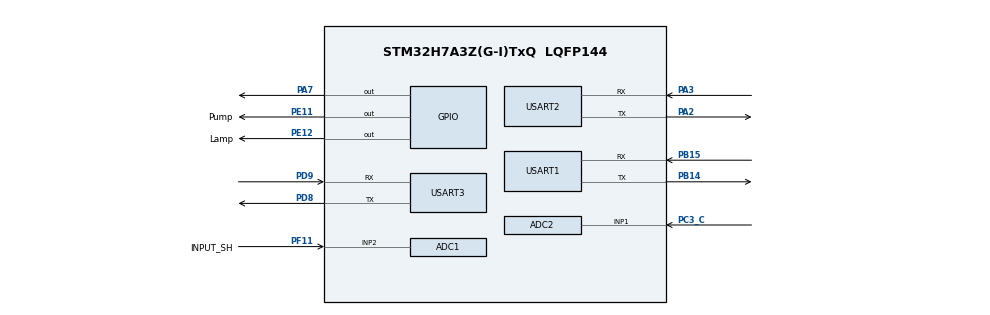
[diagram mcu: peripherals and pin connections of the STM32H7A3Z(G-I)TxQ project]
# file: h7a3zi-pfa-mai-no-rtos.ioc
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ADC1.Channel-0\#ChannelRegularConversion=ADC_CHANNEL_2
ADC1.NbrOfConversionFlag=1
ADC1.OffsetNumber-0\#ChannelRegularConversion=ADC_OFFSET_NONE
ADC1.OffsetSignedSaturation-0\#ChannelRegularConversion=DISABLE
ADC1.Rank-0\#ChannelRegularConversion=1
ADC1.SamplingTime-0\#ChannelRegularConversion=ADC_SAMPLETIME_1CYCLE_5
ADC1.master=1
ADC2.Channel-0\#ChannelRegularConversion=ADC_CHANNEL_1
ADC2.NbrOfConversionFlag=1
ADC2.OffsetNumber-0\#ChannelRegularConversion=ADC_OFFSET_NONE
ADC2.OffsetSignedSaturation-0\#ChannelRegularConversion=DISABLE
ADC2.Rank-0\#ChannelRegularConversion=1
ADC2.SamplingTime-0\#ChannelRegularConversion=ADC_SAMPLETIME_1CYCLE_5
Mcu.Family=STM32H7
Mcu.Name=STM32H7A3Z(G-I)TxQ
Mcu.Package=LQFP144
NVIC.PriorityGroup=NVIC_PRIORITYGROUP_4
PA2.Mode=Asynchronous
PA2.Signal=USART2_TX
PA3.Mode=Asynchronous
PA3.Signal=USART2_RX
PA7.Signal=GPIO_Output
PB14.Mode=Asynchronous
PB14.Signal=USART1_TX
PB15.Mode=Asynchronous
PB15.Signal=USART1_RX
PC3_C.Mode=IN1-Single-Ended
PC3_C.Signal=ADC2_INP1
PD8.Mode=Asynchronous
PD8.Signal=USART3_TX
PD9.Mode=Asynchronous
PD9.Signal=USART3_RX
PE11.GPIO_Label=Pump
PE11.Signal=GPIO_Output
PE12.GPIO_Label=Lamp
PE12.Signal=GPIO_Output
PF11.GPIO_Label=INPUT_SH
PF11.Mode=IN2-Single-Ended
PF11.Signal=ADC1_INP2
PH0-OSC_IN.Mode=HSE-External-Oscillator
PH0-OSC_IN.Signal=RCC_OSC_IN
PH1-OSC_OUT.Mode=HSE-External-Oscillator
PH1-OSC_OUT.Signal=RCC_OSC_OUT
ProjectManager.HeapSize=0x200
ProjectManager.StackSize=0x400
ProjectManager.TargetToolchain=STM32CubeIDE
RCC.ADCFreq_Value=42666666.666666664
RCC.APB1Freq_Value=64000000
RCC.APB2Freq_Value=64000000
RCC.APB3Freq_Value=64000000
RCC.APB4Freq_Value=64000000
RCC.CortexFreq_Value=64000000
RCC.DIVM1=4
RCC.DIVM2=4
RCC.DIVM3=1
RCC.DIVN1=8
RCC.DIVN2=8
RCC.DIVN3=24
RCC.DIVP2=3
RCC.DIVQ1=4
RCC.HCLKFreq_Value=64000000
RCC.HSE_VALUE=8000000
RCC.PLL2FRACN=0
RCC.PLLFRACN=0
RCC.PWR_Regulator_Voltage_Scale=PWR_REGULATOR_VOLTAGE_SCALE0
RCC.SYSCLKFreq_VALUE=64000000
RCC.SYSCLKSource=RCC_SYSCLKSOURCE_PLLCLK
RCC.SupplySource=PWR_DIRECT_SMPS_SUPPLY
RCC.USBCLockSelection=RCC_USBCLKSOURCE_HSI48
RCC.USBFreq_Value=48000000
USART1.VirtualMode-Asynchronous=VM_ASYNC
USART2.VirtualMode-Asynchronous=VM_ASYNC
USART3.VirtualMode-Asynchronous=VM_ASYNC
VP_TIM6_VS_ClockSourceINT.Mode=Enable_Timer
board=NUCLEO-H7A3ZI-Q

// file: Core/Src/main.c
/* USER CODE BEGIN Header */
/**
  ******************************************************************************
  * @file           : main.c
  * @brief          : Main program body
  ******************************************************************************
  * @attention
  *
  * Copyright (c) 2024 STMicroelectronics.
  * All rights reserved.
  *
  * This software is licensed under terms that can be found in the LICENSE file
  * in the root directory of this software component.
  * If no LICENSE file comes with this software, it is provided AS-IS.
  *
  ******************************************************************************
  */
/* USER CODE END Header */
#include "main.h"

/* USER CODE BEGIN Includes */
#include <string.h>
#include <stdio.h>
#include "DHT.h"
#include "stdint.h"
/* USER CODE END Includes */

ADC_HandleTypeDef hadc1;
ADC_HandleTypeDef hadc2;

TIM_HandleTypeDef htim6;

UART_HandleTypeDef huart1;
UART_HandleTypeDef huart2;
UART_HandleTypeDef huart3;

/* USER CODE BEGIN PV */
DHT_DataTypedef DHT11_Data;
/* USER CODE END PV */

void SystemClock_Config(void);
void PeriphCommonClock_Config(void);
static void MX_GPIO_Init(void);
static void MX_ADC1_Init(void);
static void MX_USART1_UART_Init(void);
static void MX_USART2_UART_Init(void);
static void MX_TIM6_Init(void);
static void MX_USART3_UART_Init(void);
static void MX_ADC2_Init(void);

/* USER CODE BEGIN 0 */
// Function to send a string via UART

void UART_SendString(UART_HandleTypeDef *huart, const char *str);
void UART_GetString(UART_HandleTypeDef *huart, char *str, int size);
void DHT_Init(void);
void Read_DataDHT(float *temperature, float *humidity);
float Read_Soil_Humidity(void);
float Read_Soil_Luminosity(void);
void ESP01_Init(void);
void ESP01_SendATCommands(float temperature, float humidity, float soilHumidity, float luminosity, int lamp_stat, int pump_stat);

int main(void) {
    float temperature, humidity, soilHumidity, luminosity;
    int lamp_stat = 0;
    int pump_stat = 0;
    HAL_Init();
    SystemClock_Config();
    PeriphCommonClock_Config();
    MX_GPIO_Init();
    MX_ADC1_Init();
    MX_USART1_UART_Init();
    MX_USART2_UART_Init();
    MX_TIM6_Init();
    MX_USART3_UART_Init();
    MX_ADC2_Init();

    DHT_Init();
    ESP01_Init();

    while (1) {
        Read_DataDHT(&temperature, &humidity);
        soilHumidity = Read_Soil_Humidity();
        luminosity = Read_Soil_Luminosity();

        lamp_stat = (luminosity < 100) ? 1 : 0;
        pump_stat = (soilHumidity < 30) ? 1 : 0;
        HAL_GPIO_WritePin(GPIOE, Pump_Pin, !pump_stat);
        HAL_GPIO_WritePin(GPIOE, Lamp_Pin, !lamp_stat);
        ESP01_SendATCommands(temperature, humidity, soilHumidity, luminosity, lamp_stat, pump_stat);
    }
}

void UART_SendString(UART_HandleTypeDef *huart, const char *str) {
    HAL_UART_Transmit(huart, (uint8_t*)str, strlen(str), HAL_MAX_DELAY);
}

void DHT_Init(void) {
    // Add initialization code for DHT sensor if needed
}

void Read_DataDHT(float *temperature, float *humidity) {
    DHT_GetData(&DHT11_Data);
    *temperature = DHT11_Data.Temperature;
    *humidity = DHT11_Data.Humidity;
}

float Read_Soil_Humidity(void) {
    HAL_ADC_Start(&hadc1);
    HAL_ADC_PollForConversion(&hadc1, 20);
    uint32_t adcValue = HAL_ADC_GetValue(&hadc1);
    HAL_ADC_Stop(&hadc1);
    return ((float)(65535 - adcValue) / 43535) * 100.0;
}

float Read_Soil_Luminosity(void) {
    HAL_ADC_Start(&hadc2);
    HAL_ADC_PollForConversion(&hadc2, 20);
    uint32_t adcValue = HAL_ADC_GetValue(&hadc2);
    HAL_ADC_Stop(&hadc2);
    return ((float)(65535 - adcValue) / 43535) * 100.0;
}

void ESP01_Init(void) {
    const char* commands[] = {
        "AT+CWMODE=1\r\n",
        "AT+CWJAP=\"D2F3794\",\"malek123\"\r\n",
        "AT+CIPMUX=0\r\n"
    };
    for (int i = 0; i < sizeof(commands) / sizeof(commands[0]); ++i) {
        UART_SendString(&huart2, commands[i]);
        UART_SendString(&huart3, commands[i]);
        HAL_Delay((i == 1) ? 5000 : 1000);
    }
}

void ESP01_SendATCommands(float temperature, float humidity, float soilHumidity, float luminosity, int lamp_stat, int pump_stat) {
    char cmd[256];

    // Start TCP connection
    UART_SendString(&huart2, "AT+CIPSTART=\"TCP\",\"api.thingspeak.com\",80\r\n");
    UART_SendString(&huart3, "AT+CIPSTART=\"TCP\",\"api.thingspeak.com\",80\r\n");
    HAL_Delay(250);

    // Prepare to send the sensor data
    UART_SendString(&huart2, "AT+CIPSEND=150\r\n");
    UART_SendString(&huart3, "AT+CIPSEND=150\r\n");
    HAL_Delay(250);

    snprintf(cmd, sizeof(cmd),
        "GET https://api.thingspeak.com/update?api_key=5QWLEBMD4I1BHKEA&field1=%.2f&field2=%.2f&field3=%.2f&field4=%.2f&field5=%d&field6=%d\r\n",
        temperature, humidity, soilHumidity, luminosity, lamp_stat, pump_stat);

    // Send the data
    UART_SendString(&huart2, cmd);
    UART_SendString(&huart3, cmd);
    HAL_Delay(250);
}

void SystemClock_Config(void)
{
  RCC_OscInitTypeDef RCC_OscInitStruct = {0};
  RCC_ClkInitTypeDef RCC_ClkInitStruct = {0};

  /*AXI clock gating */
  RCC->CKGAENR = 0xFFFFFFFF;

  /** Supply configuration update enable
  */
  HAL_PWREx_ConfigSupply(PWR_DIRECT_SMPS_SUPPLY);

  /** Configure the main internal regulator output voltage
  */
  __HAL_PWR_VOLTAGESCALING_CONFIG(PWR_REGULATOR_VOLTAGE_SCALE0);

  while(!__HAL_PWR_GET_FLAG(PWR_FLAG_VOSRDY)) {}

  /** Initializes the RCC Oscillators according to the specified parameters
  * in the RCC_OscInitTypeDef structure.
  */
  RCC_OscInitStruct.OscillatorType = RCC_OSCILLATORTYPE_HSI;
  RCC_OscInitStruct.HSIState = RCC_HSI_DIV1;
  RCC_OscInitStruct.HSICalibrationValue = 64;
  RCC_OscInitStruct.PLL.PLLState = RCC_PLL_ON;
  RCC_OscInitStruct.PLL.PLLSource = RCC_PLLSOURCE_HSI;
  RCC_OscInitStruct.PLL.PLLM = 4;
  RCC_OscInitStruct.PLL.PLLN = 8;
  RCC_OscInitStruct.PLL.PLLP = 2;
  RCC_OscInitStruct.PLL.PLLQ = 4;
  RCC_OscInitStruct.PLL.PLLR = 2;
  RCC_OscInitStruct.PLL.PLLRGE = RCC_PLL1VCIRANGE_3;
  RCC_OscInitStruct.PLL.PLLVCOSEL = RCC_PLL1VCOWIDE;
  RCC_OscInitStruct.PLL.PLLFRACN = 0;
  if (HAL_RCC_OscConfig(&RCC_OscInitStruct) != HAL_OK)
  {
    Error_Handler();
  }

  /** Initializes the CPU, AHB and APB buses clocks
  */
  RCC_ClkInitStruct.ClockType = RCC_CLOCKTYPE_HCLK|RCC_CLOCKTYPE_SYSCLK
                              |RCC_CLOCKTYPE_PCLK1|RCC_CLOCKTYPE_PCLK2
                              |RCC_CLOCKTYPE_D3PCLK1|RCC_CLOCKTYPE_D1PCLK1;
  RCC_ClkInitStruct.SYSCLKSource = RCC_SYSCLKSOURCE_PLLCLK;
  RCC_ClkInitStruct.SYSCLKDivider = RCC_SYSCLK_DIV1;
  RCC_ClkInitStruct.AHBCLKDivider = RCC_HCLK_DIV1;
  RCC_ClkInitStruct.APB3CLKDivider = RCC_APB3_DIV1;
  RCC_ClkInitStruct.APB1CLKDivider = RCC_APB1_DIV1;
  RCC_ClkInitStruct.APB2CLKDivider = RCC_APB2_DIV1;
  RCC_ClkInitStruct.APB4CLKDivider = RCC_APB4_DIV1;

  if (HAL_RCC_ClockConfig(&RCC_ClkInitStruct, FLASH_LATENCY_1) != HAL_OK)
  {
    Error_Handler();
  }
}

void PeriphCommonClock_Config(void)
{
  RCC_PeriphCLKInitTypeDef PeriphClkInitStruct = {0};

  /** Initializes the peripherals clock
  */
  PeriphClkInitStruct.PeriphClockSelection = RCC_PERIPHCLK_ADC;
  PeriphClkInitStruct.PLL2.PLL2M = 4;
  PeriphClkInitStruct.PLL2.PLL2N = 8;
  PeriphClkInitStruct.PLL2.PLL2P = 3;
  PeriphClkInitStruct.PLL2.PLL2Q = 2;
  PeriphClkInitStruct.PLL2.PLL2R = 2;
  PeriphClkInitStruct.PLL2.PLL2RGE = RCC_PLL2VCIRANGE_3;
  PeriphClkInitStruct.PLL2.PLL2VCOSEL = RCC_PLL2VCOWIDE;
  PeriphClkInitStruct.PLL2.PLL2FRACN = 0;
  PeriphClkInitStruct.AdcClockSelection = RCC_ADCCLKSOURCE_PLL2;
  if (HAL_RCCEx_PeriphCLKConfig(&PeriphClkInitStruct) != HAL_OK)
  {
    Error_Handler();
  }
}

static void MX_ADC1_Init(void)
{

  ADC_MultiModeTypeDef multimode = {0};
  ADC_ChannelConfTypeDef sConfig = {0};

  /** Common config
  */
  hadc1.Instance = ADC1;
  hadc1.Init.ClockPrescaler = ADC_CLOCK_ASYNC_DIV1;
  hadc1.Init.Resolution = ADC_RESOLUTION_16B;
  hadc1.Init.ScanConvMode = ADC_SCAN_DISABLE;
  hadc1.Init.EOCSelection = ADC_EOC_SINGLE_CONV;
  hadc1.Init.LowPowerAutoWait = DISABLE;
  hadc1.Init.ContinuousConvMode = DISABLE;
  hadc1.Init.NbrOfConversion = 1;
  hadc1.Init.DiscontinuousConvMode = DISABLE;
  hadc1.Init.ExternalTrigConv = ADC_SOFTWARE_START;
  hadc1.Init.ExternalTrigConvEdge = ADC_EXTERNALTRIGCONVEDGE_NONE;
  hadc1.Init.ConversionDataManagement = ADC_CONVERSIONDATA_DR;
  hadc1.Init.Overrun = ADC_OVR_DATA_PRESERVED;
  hadc1.Init.LeftBitShift = ADC_LEFTBITSHIFT_NONE;
  hadc1.Init.OversamplingMode = DISABLE;
  if (HAL_ADC_Init(&hadc1) != HAL_OK)
  {
    Error_Handler();
  }

  /** Configure the ADC multi-mode
  */
  multimode.Mode = ADC_MODE_INDEPENDENT;
  if (HAL_ADCEx_MultiModeConfigChannel(&hadc1, &multimode) != HAL_OK)
  {
    Error_Handler();
  }

  /** Configure Regular Channel
  */
  sConfig.Channel = ADC_CHANNEL_2;
  sConfig.Rank = ADC_REGULAR_RANK_1;
  sConfig.SamplingTime = ADC_SAMPLETIME_1CYCLE_5;
  sConfig.SingleDiff = ADC_SINGLE_ENDED;
  sConfig.OffsetNumber = ADC_OFFSET_NONE;
  sConfig.Offset = 0;
  sConfig.OffsetSignedSaturation = DISABLE;
  if (HAL_ADC_ConfigChannel(&hadc1, &sConfig) != HAL_OK)
  {
    Error_Handler();
  }

}

static void MX_ADC2_Init(void)
{

  ADC_ChannelConfTypeDef sConfig = {0};

  /** Common config
  */
  hadc2.Instance = ADC2;
  hadc2.Init.ClockPrescaler = ADC_CLOCK_ASYNC_DIV1;
  hadc2.Init.Resolution = ADC_RESOLUTION_16B;
  hadc2.Init.ScanConvMode = ADC_SCAN_DISABLE;
  hadc2.Init.EOCSelection = ADC_EOC_SINGLE_CONV;
  hadc2.Init.LowPowerAutoWait = DISABLE;
  hadc2.Init.ContinuousConvMode = DISABLE;
  hadc2.Init.NbrOfConversion = 1;
  hadc2.Init.DiscontinuousConvMode = DISABLE;
  hadc2.Init.ExternalTrigConv = ADC_SOFTWARE_START;
  hadc2.Init.ExternalTrigConvEdge = ADC_EXTERNALTRIGCONVEDGE_NONE;
  hadc2.Init.ConversionDataManagement = ADC_CONVERSIONDATA_DR;
  hadc2.Init.Overrun = ADC_OVR_DATA_PRESERVED;
  hadc2.Init.LeftBitShift = ADC_LEFTBITSHIFT_NONE;
  hadc2.Init.OversamplingMode = DISABLE;
  if (HAL_ADC_Init(&hadc2) != HAL_OK)
  {
    Error_Handler();
  }

  /** Configure Regular Channel
  */
  sConfig.Channel = ADC_CHANNEL_1;
  sConfig.Rank = ADC_REGULAR_RANK_1;
  sConfig.SamplingTime = ADC_SAMPLETIME_1CYCLE_5;
  sConfig.SingleDiff = ADC_SINGLE_ENDED;
  sConfig.OffsetNumber = ADC_OFFSET_NONE;
  sConfig.Offset = 0;
  sConfig.OffsetSignedSaturation = DISABLE;
  if (HAL_ADC_ConfigChannel(&hadc2, &sConfig) != HAL_OK)
  {
    Error_Handler();
  }

}

static void MX_TIM6_Init(void)
{

  TIM_MasterConfigTypeDef sMasterConfig = {0};

  htim6.Instance = TIM6;
  htim6.Init.Prescaler = 0;
  htim6.Init.CounterMode = TIM_COUNTERMODE_UP;
  htim6.Init.Period = 65535;
  htim6.Init.AutoReloadPreload = TIM_AUTORELOAD_PRELOAD_DISABLE;
  if (HAL_TIM_Base_Init(&htim6) != HAL_OK)
  {
    Error_Handler();
  }
  sMasterConfig.MasterOutputTrigger = TIM_TRGO_RESET;
  sMasterConfig.MasterSlaveMode = TIM_MASTERSLAVEMODE_DISABLE;
  if (HAL_TIMEx_MasterConfigSynchronization(&htim6, &sMasterConfig) != HAL_OK)
  {
    Error_Handler();
  }

}

static void MX_USART1_UART_Init(void)
{

  huart1.Instance = USART1;
  huart1.Init.BaudRate = 115200;
  huart1.Init.WordLength = UART_WORDLENGTH_8B;
  huart1.Init.StopBits = UART_STOPBITS_1;
  huart1.Init.Parity = UART_PARITY_NONE;
  huart1.Init.Mode = UART_MODE_TX_RX;
  huart1.Init.HwFlowCtl = UART_HWCONTROL_NONE;
  huart1.Init.OverSampling = UART_OVERSAMPLING_16;
  huart1.Init.OneBitSampling = UART_ONE_BIT_SAMPLE_DISABLE;
  huart1.Init.ClockPrescaler = UART_PRESCALER_DIV1;
  huart1.AdvancedInit.AdvFeatureInit = UART_ADVFEATURE_NO_INIT;
  if (HAL_UART_Init(&huart1) != HAL_OK)
  {
    Error_Handler();
  }
  if (HAL_UARTEx_SetTxFifoThreshold(&huart1, UART_TXFIFO_THRESHOLD_1_8) != HAL_OK)
  {
    Error_Handler();
  }
  if (HAL_UARTEx_SetRxFifoThreshold(&huart1, UART_RXFIFO_THRESHOLD_1_8) != HAL_OK)
  {
    Error_Handler();
  }
  if (HAL_UARTEx_DisableFifoMode(&huart1) != HAL_OK)
  {
    Error_Handler();
  }

}

static void MX_USART2_UART_Init(void)
{

  huart2.Instance = USART2;
  huart2.Init.BaudRate = 115200;
  huart2.Init.WordLength = UART_WORDLENGTH_8B;
  huart2.Init.StopBits = UART_STOPBITS_1;
  huart2.Init.Parity = UART_PARITY_NONE;
  huart2.Init.Mode = UART_MODE_TX_RX;
  huart2.Init.HwFlowCtl = UART_HWCONTROL_NONE;
  huart2.Init.OverSampling = UART_OVERSAMPLING_16;
  huart2.Init.OneBitSampling = UART_ONE_BIT_SAMPLE_DISABLE;
  huart2.Init.ClockPrescaler = UART_PRESCALER_DIV1;
  huart2.AdvancedInit.AdvFeatureInit = UART_ADVFEATURE_NO_INIT;
  if (HAL_UART_Init(&huart2) != HAL_OK)
  {
    Error_Handler();
  }
  if (HAL_UARTEx_SetTxFifoThreshold(&huart2, UART_TXFIFO_THRESHOLD_1_8) != HAL_OK)
  {
    Error_Handler();
  }
  if (HAL_UARTEx_SetRxFifoThreshold(&huart2, UART_RXFIFO_THRESHOLD_1_8) != HAL_OK)
  {
    Error_Handler();
  }
  if (HAL_UARTEx_DisableFifoMode(&huart2) != HAL_OK)
  {
    Error_Handler();
  }

}

static void MX_USART3_UART_Init(void)
{

  huart3.Instance = USART3;
  huart3.Init.BaudRate = 115200;
  huart3.Init.WordLength = UART_WORDLENGTH_8B;
  huart3.Init.StopBits = UART_STOPBITS_1;
  huart3.Init.Parity = UART_PARITY_NONE;
  huart3.Init.Mode = UART_MODE_TX_RX;
  huart3.Init.HwFlowCtl = UART_HWCONTROL_NONE;
  huart3.Init.OverSampling = UART_OVERSAMPLING_16;
  huart3.Init.OneBitSampling = UART_ONE_BIT_SAMPLE_DISABLE;
  huart3.Init.ClockPrescaler = UART_PRESCALER_DIV1;
  huart3.AdvancedInit.AdvFeatureInit = UART_ADVFEATURE_NO_INIT;
  if (HAL_UART_Init(&huart3) != HAL_OK)
  {
    Error_Handler();
  }
  if (HAL_UARTEx_SetTxFifoThreshold(&huart3, UART_TXFIFO_THRESHOLD_1_8) != HAL_OK)
  {
    Error_Handler();
  }
  if (HAL_UARTEx_SetRxFifoThreshold(&huart3, UART_RXFIFO_THRESHOLD_1_8) != HAL_OK)
  {
    Error_Handler();
  }
  if (HAL_UARTEx_DisableFifoMode(&huart3) != HAL_OK)
  {
    Error_Handler();
  }

}

static void MX_GPIO_Init(void)
{
  GPIO_InitTypeDef GPIO_InitStruct = {0};

  /* GPIO Ports Clock Enable */
  __HAL_RCC_GPIOH_CLK_ENABLE();
  __HAL_RCC_GPIOC_CLK_ENABLE();
  __HAL_RCC_GPIOA_CLK_ENABLE();
  __HAL_RCC_GPIOF_CLK_ENABLE();
  __HAL_RCC_GPIOE_CLK_ENABLE();
  __HAL_RCC_GPIOB_CLK_ENABLE();
  __HAL_RCC_GPIOD_CLK_ENABLE();

  /*Configure GPIO pin Output Level */
  HAL_GPIO_WritePin(GPIOA, GPIO_PIN_7, GPIO_PIN_RESET);

  /*Configure GPIO pin Output Level */
  HAL_GPIO_WritePin(GPIOE, Pump_Pin|Lamp_Pin, GPIO_PIN_RESET);

  /*Configure GPIO pin : PA7 */
  GPIO_InitStruct.Pin = GPIO_PIN_7;
  GPIO_InitStruct.Mode = GPIO_MODE_OUTPUT_PP;
  GPIO_InitStruct.Pull = GPIO_NOPULL;
  GPIO_InitStruct.Speed = GPIO_SPEED_FREQ_LOW;
  HAL_GPIO_Init(GPIOA, &GPIO_InitStruct);

  /*Configure GPIO pins : Pump_Pin Lamp_Pin */
  GPIO_InitStruct.Pin = Pump_Pin|Lamp_Pin;
  GPIO_InitStruct.Mode = GPIO_MODE_OUTPUT_PP;
  GPIO_InitStruct.Pull = GPIO_NOPULL;
  GPIO_InitStruct.Speed = GPIO_SPEED_FREQ_LOW;
  HAL_GPIO_Init(GPIOE, &GPIO_InitStruct);

}

void Error_Handler(void)
{
  __disable_irq();
  while (1)
  {
  }
}
